# SIM3L164_C register map
File version: 1
CPU: 
Registers are 32-bit, read-write, reset 0x0 unless marked. A register's access mark holds for its fields unless they carry their own. Offsets are from the block's base; [hi:lo] are bit positions.

## DCDC_0
Base 0x4004E000
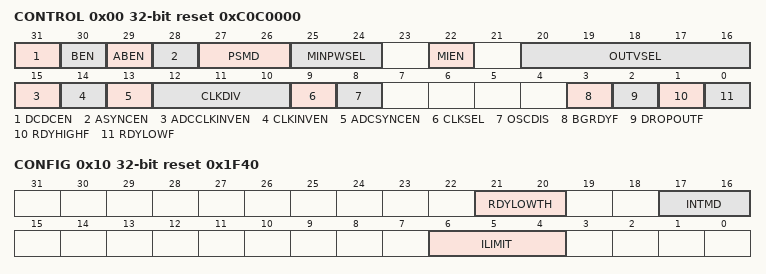
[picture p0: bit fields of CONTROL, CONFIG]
0x00 CONTROL reset 0xC0C0000 — Module Control
  [31] DCDCEN — DC-DC Converter Enable.
    0=DISABLED (Disable the DC-DC converter.); 1=ENABLED (Enable the DC-DC converter.)
  [30] BEN — Bypass Enable.
    0=DISABLED (Disable the MBYP bypass switch.); 1=ENABLED (Enable the MBYP bypass switch.)
  [29] ABEN — Automatic Bypass Enable.
    0=DISABLED (Disable automatic bypass.); 1=ENABLED (Enable automatic bypass.)
  [28] ASYNCEN — Asynchronous Mode Enable.
    0=DISABLED (Enable DC-DC synchronous mode.); 1=ENABLED (Enable DC-DC asynchronous mode. This mode is more efficient for very light output loads.)
  [27:26] PSMD — Power Switch Mode.
    0=SWSEL0 (Mode 0. Set the M1 and M2 power switches to each use one MOSFET only.); 1=SWSEL1 (Mode 1. Set the M1 and M2 power switches to each use 2 MOSFETS in parallel.); 2=SWSEL2 (Mode 2. Set the M1 and M2 power switches to each use 3 MOSFETS in parallel.); 3=SWSEL3 (Mode 3. Set the M1 and M2 power switches to each use 4 MOSFETS in parallel.)
  [25:24] MINPWSEL — Minimum Pulse Width Select.
    0=DISABLED (Disable pulse skipping.); 1=10_NS (Set the minimum pulse width to 10 ns.); 2=20_NS (Set the minimum pulse width to 20 ns.); 3=40_NS (Set the minimum pulse width to 40 ns.)
  [22] MIEN — Module Interrupt Enable.
    0=DISABLED (Disable DC-DC module interrupts.); 1=ENABLED (Enable DC-DC module interrupts.)
  [20:16] OUTVSEL — Output Voltage Select.
  [15] ADCCLKINVEN — ADC Clock Inversion Enable.
    0=DISABLED (Do not invert the ADC clock derived from the DC-DC switching frequency.); 1=ENABLED (Invert the ADC clock derived from the DC-DC switching frequency.)
  [14] CLKINVEN — Clock Inversion Enable.
    0=DISABLED (Do not invert the APB clock input.); 1=ENABLED (Invert the APB clock input.)
  [13] ADCSYNCEN — ADC Synchronization Enable.
    0=DISABLED (Do not synchronize the ADC to the DC-DC converter.); 1=ENABLED (Synchronize the ADC to the DC-DC converter.)
  [12:10] CLKDIV — Clock Divider.
    0=DIV1 (Use the APB clock divided by 1 as the converter switching frequency.); 1=DIV2 (Use the APB clock divided by 2 as the converter switching frequency.); 2=DIV4 (Use the APB clock divided by 4 as the converter switching frequency.); 3=DIV8 (Use the APB clock divided by 8 as the converter switching frequency.); 4=DIV16 (Use the APB clock divided by 16 as the converter switching frequency.)
  [9] CLKSEL — Clock Source Select.
    0=DCDCOSC (Select the local DC-DC oscillator as the clock source.); 1=APB (Select the APB clock as the clock source.)
  [8] OSCDIS — Oscillator Disable.
    0=INACTIVE (Enable the DC-DC local oscillator.); 1=ACTIVE (Disable the DC-DC local oscillator.)
  [3] BGRDYF ro — Bandgap Ready Flag.
    0=NOT_SET (The bandgap voltage is not above the threshold.); 1=SET (The bandgap voltage is above the threshold.)
  [2] DROPOUTF ro — DC-DC Converter Dropout Flag.
    0=NOT_SET (The input voltage (VBATDC) is more than 0.4 V above the output voltage (VDC). The DC-DC converter is not in dropout.); 1=SET (The input voltage (VBATDC) is less than 0.4 V above the output voltage (VDC). The DC-DC converter is in dropout, and firmware should enable the bypass switch (BEN=1).)
  [1] RDYHIGHF ro — DC-DC Converter Ready High Flag.
    0=NOT_SET (The output voltage (VDC) has not exceeded 105% of the programmed output value.); 1=SET (The output voltage (VDC) has exceeded 105% of the programmed output value.)
  [0] RDYLOWF ro — DC-DC Converter Ready Low Flag.
    0=NOT_SET (The output voltage (VDC) is below the threshold set in the RDYLOWTH threshold field (RDYLOWTH).); 1=SET (The output voltage (VDC) is above the threshold set in the RDYLOWTH threshold field (RDYLOWTH).)
0x10 CONFIG reset 0x1F40 — Module Configuration
  [21:20] RDYLOWTH — Converter Ready Low Threshold.
    0=95_PERCENT (Hardware sets the RDYLOWF flag if the regulated output voltage is greater than 95% of the programmed output voltage.); 1=90_PERCENT (Hardware sets the RDYLOWF flag if the regulated output voltage is greater than 90% of the programmed output voltage.); 2=85_PERCENT (Hardware sets the RDYLOWF flag if the regulated output voltage is greater than 85% of the programmed output voltage.); 3=80_PERCENT (Hardware sets the RDYLOWF flag if the regulated output voltage is greater than 80% of the programmed output voltage.)
  [17:16] INTMD — Interrupt Mode.
    0=OUTPUT_TOO_LOW (Generate an interrupt when the regulated converter output voltage is too low, according to the RDYLOWF flag.); 1=OUTPUT_NOT_TOO_LOW (Generate an interrupt when the regulated converter output voltage is not too low according to the RDYLOWF flag.); 2=OUT_OF_REG (Generate an interrupt when the output voltage is out of regulation. The converter output can be either too high or too low, according to the RDYLOWF and RDYHIGHF flags.); 3=IN_REG (Generate an interrupt when the output voltage is in regulation.)
  [6:4] ILIMIT — Inductor Peak Current Limit.
    1=LIMIT1 (Limit the peak inductor current to 200 mA.); 2=LIMIT2 (Limit the peak inductor current to 300 mA.); 3=LIMIT3 (Limit the peak inductor current to 400 mA.); 4=LIMIT4 (Limit the peak inductor current to 500 mA.); 5=LIMIT5 (Limit the peak inductor current to 600 mA.); 6=LIMIT6 (Limit the peak inductor current to 700 mA.); 7=LIMIT7 (Limit the peak inductor current to 800 mA.)
